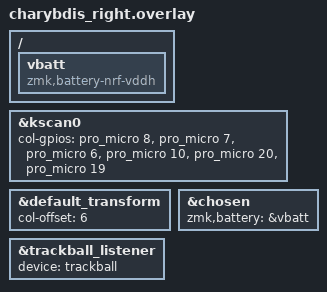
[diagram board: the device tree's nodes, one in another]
#include "charybdis.dtsi"
#include "driver_pmw3610.dtsi"
#include <dt-bindings/zmk/input_transform.h>

&kscan0 {
	col-gpios
		= <&pro_micro 8 (GPIO_ACTIVE_HIGH | GPIO_PULL_DOWN)>
		, <&pro_micro 7 (GPIO_ACTIVE_HIGH | GPIO_PULL_DOWN)>
		, <&pro_micro 6 (GPIO_ACTIVE_HIGH | GPIO_PULL_DOWN)>
		, <&pro_micro 10 (GPIO_ACTIVE_HIGH | GPIO_PULL_DOWN)>
		, <&pro_micro 20 (GPIO_ACTIVE_HIGH | GPIO_PULL_DOWN)>
		, <&pro_micro 19 (GPIO_ACTIVE_HIGH | GPIO_PULL_DOWN)>
		;
};

&default_transform { // Offset of 6 because the left side has 6 columns
    col-offset = <6>;
};

&chosen {
	zmk,battery = &vbatt;
};

&trackball_listener {
	status = "okay";
  	device = <&trackball>;
};

/{
    vbatt: vbatt {
	    compatible = "zmk,battery-nrf-vddh";
    };
};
